# RX64M_USB0_Pilot register map
File version: 1.0
RX64M_USB0_Pilot peripheral registers generated from iodefine.h (pilot).
Registers are 16-bit, read-write, reset 0x0 unless marked. A register's access mark holds for its fields unless they carry their own. Offsets are from the block's base; lines under a group give offsets from that group; [hi:lo] are bit positions; {n}, {i} and the like mark numbered series; 'fields as' and 'values as' point back to an identical list; <NAME> marks a mode.

## Memory map
0x000A0000 USB0 size 0xF4

## USB0
Base 0x000A0000
0x00 SYSCFG
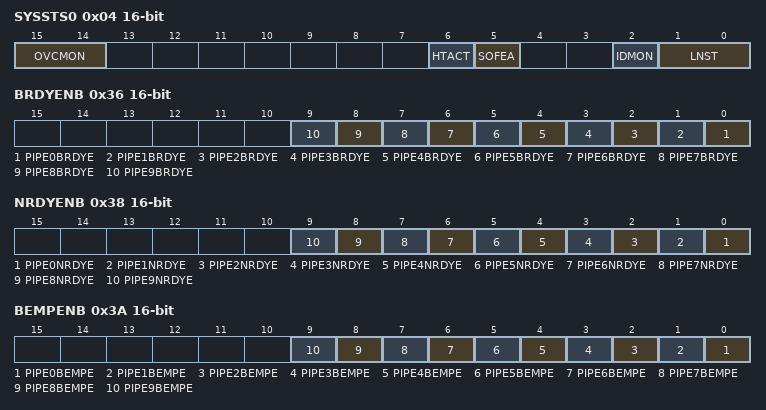
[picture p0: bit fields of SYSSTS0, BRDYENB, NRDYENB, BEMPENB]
0x04 SYSSTS0 ro
  [15:14] OVCMON, [6] HTACT, [5] SOFEA, [2] IDMON, [1:0] LNST
0x08 DVSTCTR0
0x14 CFIFO
0x18 D0FIFO
0x1C D1FIFO
0x20 CFIFOSEL
0x22 CFIFOCTR
0x28 D0FIFOSEL
0x2A D0FIFOCTR
0x2C D1FIFOSEL
0x2E D1FIFOCTR
0x30 INTENB0
0x32 INTENB1
0x36 BRDYENB
  [n] PIPE{n}BRDYE (n=0..9)
0x38 NRDYENB
  [n] PIPE{n}NRDYE (n=0..9)
0x3A BEMPENB
  [n] PIPE{n}BEMPE (n=0..9)
0x3C SOFCFG
0x40 INTSTS0
0x42 INTSTS1
0x46 BRDYSTS
0x48 NRDYSTS
0x4A BEMPSTS
0x4C FRMNUM
0x4E DVCHGR
  [15] DVCHG
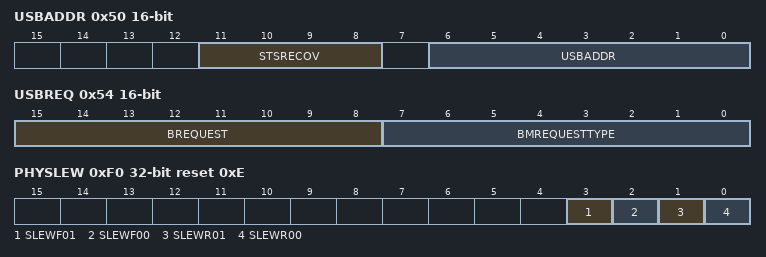
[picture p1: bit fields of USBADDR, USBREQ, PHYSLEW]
0x50 USBADDR
  [11:8] STSRECOV, [6:0] USBADDR
0x54 USBREQ
  [15:8] BREQUEST, [7:0] BMREQUESTTYPE
0x56 USBVAL
0x58 USBINDX
0x5A USBLENG
0x5C DCPCFG
0x5E DCPMAXP reset 0x40
0x60 DCPCTR reset 0x40
0x64 PIPESEL
0x68 PIPECFG
0x6C PIPEMAXP
0x6E PIPEPERI
{0x6E+2i} PIPE{i}CTR (i=1..9)
{0x8C+4i} PIPE{i}TRE (i=1..5)
{0x8E+4i} PIPE{i}TRN (i=1..5)
{0xD0+2i} DEVADD{i} (i=0..5)
0xF0 PHYSLEW 32-bit reset 0xE
  [3] SLEWF01, [2] SLEWF00, [1] SLEWR01, [0] SLEWR00
